# NUC100BN_v1 register map
File version: 1.0
Registers are 32-bit, read-write, reset 0x0 unless marked. A register's access mark holds for its fields unless they carry their own. Offsets are from the block's base; [hi:lo] are bit positions.

## RTC — RTC Register Map
Base 0x40008000
0x00 INIR — RTC Initiation Register
  [31:0] INIR wo — RTC Initiation (Write only). When RTC block is powered on, RTC is at reset state. User has to write a number (0x a5eb1357) to INIR to make RTC leaving reset state. Once the INIR is written as 0xa5eb1357, the RTC will be in un-reset state permanently. The INIR is a write-only field and read value will be always "0". RTC Active Status (Read only)
    0=RTC is at reset state; 1=RTC is at normal active state
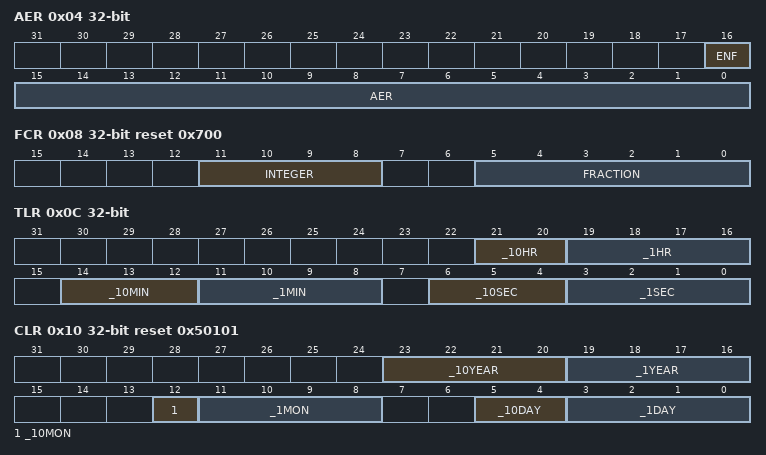
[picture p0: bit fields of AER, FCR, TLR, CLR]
0x04 AER — RTC Access Enable Register
  [16] ENF ro — RTC Register Access Enable Flag (Read only)
    0=RTC register read/write Disabled; 1=RTC register read/write Enabled
  [15:0] AER wo — RTC Register Access Enable Password (Write Only). Writing 0xA965 to this register will enable RTC access and keep 1024 RTC clock
0x08 FCR reset 0x700 — RTC Frequency Compensation Register
  [11:8] INTEGER — Integer Part
  [5:0] FRACTION — Fraction Part. Note: Digit in FCR must be expressed as hexadecimal number. Refer to 5.8.4.4 for the examples.
0x0C TLR — Time Loading Register
  [21:20] _10HR — 10-Hour Time Digit (0~2)
  [19:16] _1HR — 1-Hour Time Digit (0~9)
  [14:12] _10MIN — 10-Min Time Digit (0~5)
  [11:8] _1MIN — 1-Min Time Digit (0~9)
  [6:4] _10SEC — 10-Sec Time Digit (0~5)
  [3:0] _1SEC — 1-Sec Time Digit (0~9)
0x10 CLR reset 0x50101 — Calendar Loading Register
  [23:20] _10YEAR — 10-Year Calendar Digit (0~9)
  [19:16] _1YEAR — 1-Year Calendar Digit (0~9)
  [12] _10MON — 10-Month Calendar Digit (0~1)
  [11:8] _1MON — 1-Month Calendar Digit (0~9)
  [5:4] _10DAY — 10-Day Calendar Digit (0~3)
  [3:0] _1DAY — 1-Day Calendar Digit (0~9)
0x14 TSSR reset 0x1 — Time Scale Selection Register
  [0] _24H_12H — 24-Hour / 12-Hour Time Scale Selection
    0=Selected as 12-hour time scale with AM and PM indication; 1=Selected as 24-hour time scale
0x18 DWR reset 0x6 — Day of the Week Register
  [2:0] DWR
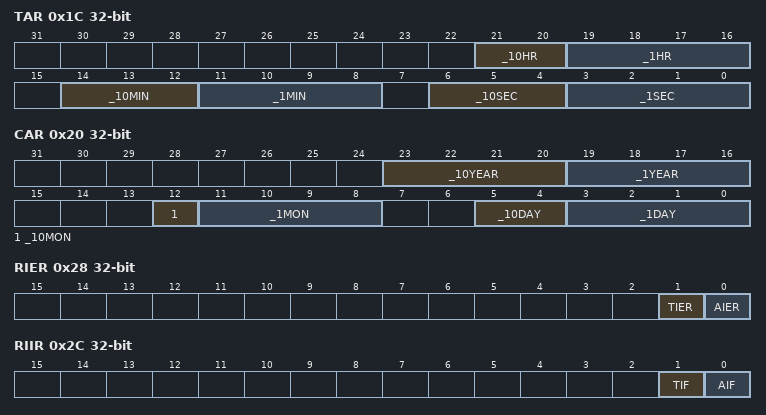
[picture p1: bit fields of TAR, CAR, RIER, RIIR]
0x1C TAR — Time Alarm Register
  [21:20] _10HR — 10-Hour Time Digit of Alarm Setting (0~2)
  [19:16] _1HR — 1-Hour Time Digit of Alarm Setting (0~9)
  [14:12] _10MIN — 10-Min Time Digit of Alarm Setting (0~5)
  [11:8] _1MIN — 1-Min Time Digit of Alarm Setting (0~9)
  [6:4] _10SEC — 10-Sec Time Digit of Alarm Setting (0~5)
  [3:0] _1SEC — 1-Sec Time Digit of Alarm Setting (0~9)
0x20 CAR — Calendar Alarm Register
  [23:20] _10YEAR — 10-Year Calendar Digit of Alarm Setting (0~9)
  [19:16] _1YEAR — 1-Year Calendar Digit of Alarm Setting (0~9)
  [12] _10MON — 10-Month Calendar Digit of Alarm Setting (0~1)
  [11:8] _1MON — 1-Month Calendar Digit of Alarm Setting (0~9)
  [5:4] _10DAY — 10-Day Calendar Digit of Alarm Setting (0~3)
  [3:0] _1DAY — 1-Day Calendar Digit of Alarm Setting (0~9)
0x24 LIR ro — Leap Year Indicator Register
  [0] LIR — Leap Year Indication Register (Read Only)
    0=This year is not a leap year; 1=This year is leap year
0x28 RIER — RTC Interrupt Enable Register
  [1] TIER — Time Tick Interrupt Enable
    0=RTC Time Tick Interrupt Disabled; 1=RTC Time Tick Interrupt Enabled
  [0] AIER — Alarm Interrupt Enable
    0=RTC Alarm Interrupt Disabled; 1=RTC Alarm Interrupt Enabled
0x2C RIIR — RTC Interrupt Indicator Register
  [1] TIF — RTC Time Tick Interrupt Flag
    0=RCT Time Tick Interrupt condition never occurred; 1=RTC Time Tick Interrupt is requested if RIER.TIER = 1
  [0] AIF — RTC Alarm Interrupt Flag
    0=RCT Alarm Interrupt condition never occurred; 1=RTC Alarm Interrupt is requested if RIER.AIER = 1
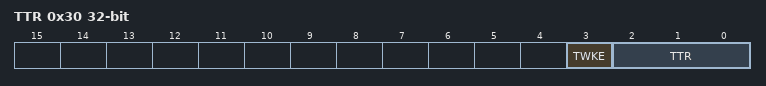
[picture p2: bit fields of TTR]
0x30 TTR — RTC Time Tick Register
  [3] TWKE — RTC Timer Wake-up Function Enable. If TWKE is set before chip is in Power-down mode, chip will be woken up by RTC controller when a RTC Time Tick occurs. Note1: Tick timer setting follows the TTR[2:0] description. Note2: When Alarm Match occurs, chip will be woken up from Power-down mode no matter TWKE is 1 or 0.
    0=RTC Timer wake-up Disabled by Timer Tick occur function; 1=RTC Timer wake-up function Enabled so that chip can be woken up from Power-down mode by Time Tick
  [2:0] TTR — Time Tick Register
